AUTOSAR XML (schema 00046)
package /ComponentTypes
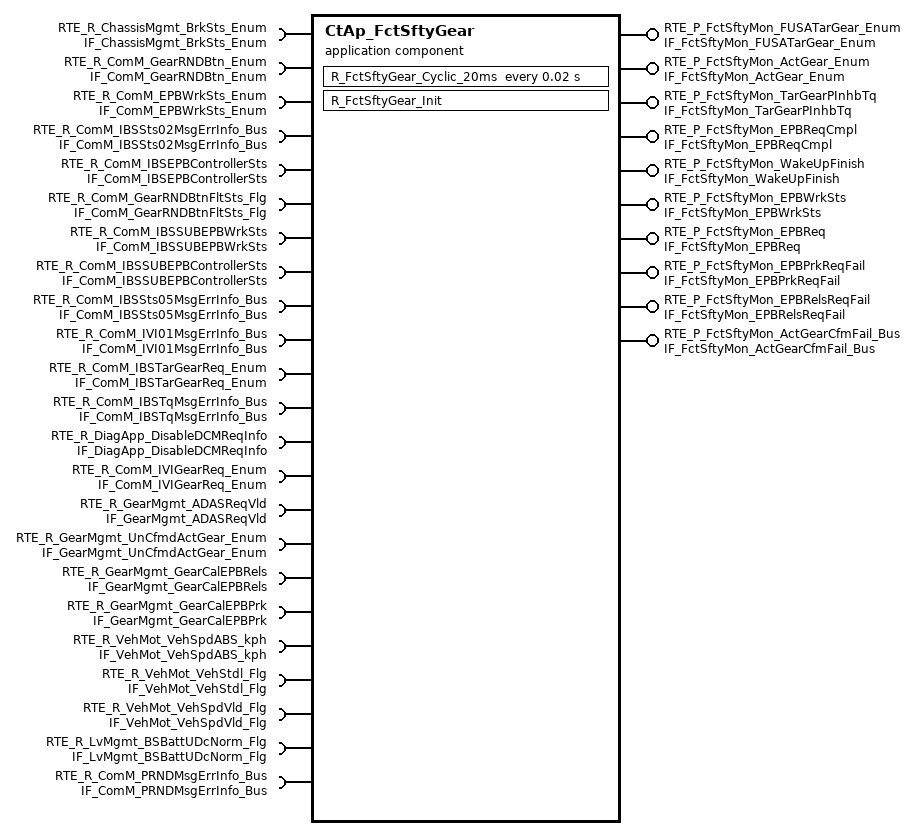
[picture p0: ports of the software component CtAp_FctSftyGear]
  application sw component type CtAp_FctSftyGear
    9 x provide port:
      RTE_P_FctSftyMon_FUSATarGear_Enum: nonqueued-sender-com-spec{data-element=tec_FctSftyMon_FUSATarGear_Enum, init-value=0}, provided-interface=IF_FctSftyMon_FUSATarGear_Enum
      RTE_P_FctSftyMon_ActGear_Enum: nonqueued-sender-com-spec{data-element=tec_FctSftyMon_ActGear_Enum, init-value=0}, provided-interface=IF_FctSftyMon_ActGear_Enum
      RTE_P_FctSftyMon_TarGearPInhbTq: nonqueued-sender-com-spec{data-element=tec_FctSftyMon_TarGearPInhbTq, init-value=0}, provided-interface=IF_FctSftyMon_TarGearPInhbTq
      RTE_P_FctSftyMon_EPBReqCmpl: nonqueued-sender-com-spec{data-element=tec_FctSftyMon_EPBReqCmpl, init-value=0}, provided-interface=IF_FctSftyMon_EPBReqCmpl
      RTE_P_FctSftyMon_WakeUpFinish: nonqueued-sender-com-spec{data-element=tec_FctSftyMon_WakeUpFinish, init-value=0}, provided-interface=IF_FctSftyMon_WakeUpFinish
      RTE_P_FctSftyMon_EPBWrkSts: nonqueued-sender-com-spec{data-element=tec_FctSftyMon_EPBWrkSts, init-value=0}, provided-interface=IF_FctSftyMon_EPBWrkSts
      RTE_P_FctSftyMon_EPBReq: nonqueued-sender-com-spec{data-element=tec_FctSftyMon_EPBReq, init-value=0}, provided-interface=IF_FctSftyMon_EPBReq
      RTE_P_FctSftyMon_EPBPrkReqFail: nonqueued-sender-com-spec{data-element=tec_FctSftyMon_EPBPrkReqFail, init-value=0}, provided-interface=IF_FctSftyMon_EPBPrkReqFail
      RTE_P_FctSftyMon_EPBRelsReqFail: nonqueued-sender-com-spec{data-element=tec_FctSftyMon_EPBRelsReqFail, init-value=0}, provided-interface=IF_FctSftyMon_EPBRelsReqFail
    provide/require port RTE_RP_GearMgmtInfo: nv-provide-com-spec{ram-block-init-value=fields=[GearMgmt_GearMemInfo_Enum:0, GearMgmt_FillAddress:0], rom-block-init-value=fields=[GearMgmt_GearMemInfo_Enum:0, GearMgmt_FillAddress:0], variable=tec_GearMgmtInfo}, nv-require-com-spec{init-value=fields=[GearMgmt_GearMemInfo_Enum:0, GearMgmt_FillAddress:0], variable=tec_GearMgmtInfo}, provided-required-interface=IF_GearMgmtInfo
    14 x require port:
      RTE_R_ChassisMgmt_BrkSts_Enum: nonqueued-receiver-com-spec{data-element=tec_ChassisMgmt_BrkSts_Enum, filter=data-filter-type=ALWAYS, init-value=0}, required-interface=IF_ChassisMgmt_BrkSts_Enum
      RTE_R_ComM_GearRNDBtn_Enum: nonqueued-receiver-com-spec{data-element=tec_ComM_GearRNDBtn_Enum, filter=data-filter-type=ALWAYS, init-value=0}, required-interface=IF_ComM_GearRNDBtn_Enum
      RTE_R_ComM_EPBWrkSts_Enum: nonqueued-receiver-com-spec{data-element=tec_ComM_EPBWrkSts_Enum, filter=data-filter-type=ALWAYS, init-value=0}, required-interface=IF_ComM_EPBWrkSts_Enum
      RTE_R_ComM_IBSSts02MsgErrInfo_Bus: required-interface=IF_ComM_IBSSts02MsgErrInfo_Bus
        required-com-specs:
          data-element=tec_ComM_IBSSts02CRCInfo_Bus, filter=data-filter-type=ALWAYS, init-value=fields=[ComM_MonStatIBSSts02CRCErrorInfo:0, ComM_MonResIBSSts02CRCErrorInfo:0, ComM_ErrStatIBSSts02CRCErrorInfo:0, ComM_ErrResIBSSts02CRCErrorInfo:0]
          data-element=tec_ComM_IBSSts02CRCDTCInfo_Bus, filter=data-filter-type=ALWAYS, init-value=fields=[ComM_MonStatIBSSts02CRCDTCErrorInfo:0, ComM_MonResIBSSts02CRCDTCErrorInfo:0, ComM_ErrStatIBSSts02CRCDTCErrorInfo:0, ComM_ErrResIBSSts02CRCDTCErrorInfo:0]
          data-element=tec_ComM_IBSSts02TimeoutDTCInfo_Bus, filter=data-filter-type=ALWAYS, init-value=fields=[ComM_MonStatIBSSts02TimeoutDTCErrorInfo:0, ComM_MonResIBSSts02TimeoutDTCErrorInfo:0, ComM_ErrStatIBSSts02TimeoutDTCErrorInfo:0, ComM_ErrResIBSSts02TimeoutDTCErrorInfo:0]
          data-element=tec_ComM_IBSSts02E2ETimeoutInfo_Bus, filter=data-filter-type=ALWAYS, init-value=fields=[ComM_MonStatIBSSts02E2ETimeoutInfo:0, ComM_MonResIBSSts02E2ETimeoutInfo:0, ComM_ErrStatIBSSts02E2ETimeoutInfo:0, ComM_ErrResIBSSts02E2ETimeoutInfo:0]
      RTE_R_ComM_IBSEPBControllerSts: nonqueued-receiver-com-spec{data-element=tec_ComM_IBSEPBControllerSts, filter=data-filter-type=ALWAYS, init-value=0}, required-interface=IF_ComM_IBSEPBControllerSts
      RTE_R_ComM_GearRNDBtnFltSts_Flg: nonqueued-receiver-com-spec{data-element=tec_ComM_GearRNDBtnFltSts_Flg, filter=data-filter-type=ALWAYS, init-value=0}, required-interface=IF_ComM_GearRNDBtnFltSts_Flg
      RTE_R_ComM_IBSSUBEPBWrkSts: nonqueued-receiver-com-spec{data-element=tec_ComM_IBSSUBEPBWrkSts, filter=data-filter-type=ALWAYS, init-value=0}, required-interface=IF_ComM_IBSSUBEPBWrkSts
      RTE_R_ComM_IBSSUBEPBControllerSts: nonqueued-receiver-com-spec{data-element=tec_ComM_IBSSUBEPBControllerSts, filter=data-filter-type=ALWAYS, init-value=0}, required-interface=IF_ComM_IBSSUBEPBControllerSts
      RTE_R_ComM_IBSSts05MsgErrInfo_Bus: required-interface=IF_ComM_IBSSts05MsgErrInfo_Bus
        required-com-specs:
          data-element=tec_ComM_IBSSts05CRCDTCInfo_Bus, filter=data-filter-type=ALWAYS, init-value=fields=[ComM_MonStatIBSSts05CRCDTCErrorInfo:0, ComM_MonResIBSSts05CRCDTCErrorInfo:0, ComM_ErrStatIBSSts05CRCDTCErrorInfo:0, ComM_ErrResIBSSts05CRCDTCErrorInfo:0]
          data-element=tec_ComM_IBSSts05TimeoutDTCInfo_Bus, filter=data-filter-type=ALWAYS, init-value=fields=[ComM_MonStatIBSSts05TimeoutDTCErrorInfo:0, ComM_MonResIBSSts05TimeoutDTCErrorInfo:0, ComM_ErrStatIBSSts05TimeoutDTCErrorInfo:0, ComM_ErrResIBSSts05TimeoutDTCErrorInfo:0]
          data-element=tec_ComM_IBSSts05TimeoutInfo_Bus, filter=data-filter-type=ALWAYS, init-value=fields=[ComM_MonStatIBSSts05TimeoutInfo:0, ComM_MonResIBSSts05TimeoutInfo:0, ComM_ErrStatIBSSts05TimeoutInfo:0, ComM_ErrResIBSSts05TimeoutInfo:0]
          data-element=tec_ComM_IBSSts05CRCInfo_Bus, filter=data-filter-type=ALWAYS, init-value=fields=[ComM_MonStatIBSSts05CRCErrorInfo:0, ComM_MonResIBSSts05CRCErrorInfo:0, ComM_ErrStatIBSSts05CRCErrorInfo:0, ComM_ErrResIBSSts05CRCErrorInfo:0]
          data-element=tec_ComM_IBSSts05E2ETimeoutInfo_Bus, filter=data-filter-type=ALWAYS, init-value=fields=[ComM_MonStatIBSSts05E2ETimeoutInfo:0, ComM_MonResIBSSts05E2ETimeoutInfo:0, ComM_ErrStatIBSSts05E2ETimeoutInfo:0, ComM_ErrResIBSSts05E2ETimeoutInfo:0]
      RTE_R_ComM_IVI01MsgErrInfo_Bus: required-interface=IF_ComM_IVI01MsgErrInfo_Bus
        required-com-specs:
          data-element=tec_ComM_IVI01CRCInfo_Bus, filter=data-filter-type=ALWAYS, init-value=fields=[ComM_MonStatIVI01CRCErrorInfo:0, ComM_MonResIVI01CRCErrorInfo:0, ComM_ErrStatIVI01CRCErrorInfo:0, ComM_ErrResIVI01CRCErrorInfo:0]
          data-element=tec_ComM_IVI01E2ETimeoutInfo_Bus, filter=data-filter-type=ALWAYS, init-value=fields=[ComM_MonStatIVI01E2ETimeoutInfo:0, ComM_MonResIVI01E2ETimeoutInfo:0, ComM_ErrStatIVI01E2ETimeoutInfo:0, ComM_ErrResIVI01E2ETimeoutInfo:0]
      RTE_R_ComM_IBSTarGearReq_Enum: nonqueued-receiver-com-spec{data-element=tec_ComM_IBSTarGearReq_Enum, filter=data-filter-type=ALWAYS, init-value=0}, required-interface=IF_ComM_IBSTarGearReq_Enum
      RTE_R_ComM_IBSTqMsgErrInfo_Bus: required-interface=IF_ComM_IBSTqMsgErrInfo_Bus
        required-com-specs:
          data-element=tec_ComM_IBSTqCRCDTCInfo_Bus, filter=data-filter-type=ALWAYS, init-value=fields=[ComM_MonStatIBSTqCRCDTCErrorInfo:0, ComM_MonResIBSTqCRCDTCErrorInfo:0, ComM_ErrStatIBSTqCRCDTCErrorInfo:0, ComM_ErrResIBSTqCRCDTCErrorInfo:0]
          data-element=tec_ComM_IBSTqTimeoutDTCInfo_Bus, filter=data-filter-type=ALWAYS, init-value=fields=[ComM_MonStatIBSTqTimeoutDTCErrorInfo:0, ComM_MonResIBSTqTimeoutDTCErrorInfo:0, ComM_ErrStatIBSTqTimeoutDTCErrorInfo:0, ComM_ErrResIBSTqTimeoutDTCErrorInfo:0]
          data-element=tec_ComM_IBSTqCRCInfo_Bus, filter=data-filter-type=ALWAYS, init-value=fields=[ComM_MonStatIBSTqCRCErrorInfo:0, ComM_MonResIBSTqCRCErrorInfo:0, ComM_ErrStatIBSTqCRCErrorInfo:0, ComM_ErrResIBSTqCRCErrorInfo:0]
          data-element=tec_ComM_IBSTqE2ETimeoutInfo_Bus, filter=data-filter-type=ALWAYS, init-value=fields=[ComM_MonStatIBSTqE2ETimeoutInfo:0, ComM_MonResIBSTqE2ETimeoutInfo:0, ComM_ErrStatIBSTqE2ETimeoutInfo:0, ComM_ErrResIBSTqE2ETimeoutInfo:0]
      RTE_R_DiagApp_DisableDCMReqInfo: nonqueued-receiver-com-spec{data-element=tec_DiagApp_DisableDCMReqInfo, filter=data-filter-type=ALWAYS, init-value=0}, required-interface=IF_DiagApp_DisableDCMReqInfo
      RTE_R_ComM_IVIGearReq_Enum: nonqueued-receiver-com-spec{data-element=tec_ComM_IVIGearReq_Enum, filter=data-filter-type=ALWAYS, init-value=0}, required-interface=IF_ComM_IVIGearReq_Enum
    provide port RTE_P_FctSftyMon_ActGearCfmFail_Bus: nonqueued-sender-com-spec{data-element=tec_FctSftyMon_ActGearCfmFail_Bus, init-value=fields=[FctSftyMon_MonStatActGearCfmFail:0, FctSftyMon_MonResActGearCfmFail:0, FctSftyMon_ErrStatActGearCfmFail:0, FctSftyMon_ErrResActGearCfmFail:0]}, provided-interface=IF_FctSftyMon_ActGearCfmFail_Bus
    9 x require port:
      RTE_R_GearMgmt_ADASReqVld: nonqueued-receiver-com-spec{data-element=tec_GearMgmt_ADASReqVld, filter=data-filter-type=ALWAYS, init-value=0}, required-interface=IF_GearMgmt_ADASReqVld
      RTE_R_GearMgmt_UnCfmdActGear_Enum: nonqueued-receiver-com-spec{data-element=tec_GearMgmt_UnCfmdActGear_Enum, filter=data-filter-type=ALWAYS, init-value=0}, required-interface=IF_GearMgmt_UnCfmdActGear_Enum
      RTE_R_GearMgmt_GearCalEPBRels: nonqueued-receiver-com-spec{data-element=tec_GearMgmt_GearCalEPBRels, filter=data-filter-type=ALWAYS, init-value=0}, required-interface=IF_GearMgmt_GearCalEPBRels
      RTE_R_GearMgmt_GearCalEPBPrk: nonqueued-receiver-com-spec{data-element=tec_GearMgmt_GearCalEPBPrk, filter=data-filter-type=ALWAYS, init-value=0}, required-interface=IF_GearMgmt_GearCalEPBPrk
      RTE_R_VehMot_VehSpdABS_kph: nonqueued-receiver-com-spec{data-element=tec_VehMot_VehSpdABS_kph, filter=data-filter-type=ALWAYS, init-value=0}, required-interface=IF_VehMot_VehSpdABS_kph
      RTE_R_VehMot_VehStdl_Flg: nonqueued-receiver-com-spec{data-element=tec_VehMot_VehStdl_Flg, filter=data-filter-type=ALWAYS, init-value=0}, required-interface=IF_VehMot_VehStdl_Flg
      RTE_R_VehMot_VehSpdVld_Flg: nonqueued-receiver-com-spec{data-element=tec_VehMot_VehSpdVld_Flg, filter=data-filter-type=ALWAYS, init-value=0}, required-interface=IF_VehMot_VehSpdVld_Flg
      RTE_R_LvMgmt_BSBattUDcNorm_Flg: nonqueued-receiver-com-spec{data-element=tec_LvMgmt_BSBattUDcNorm_Flg, filter=data-filter-type=ALWAYS, init-value=0}, required-interface=IF_LvMgmt_BSBattUDcNorm_Flg
      RTE_R_ComM_PRNDMsgErrInfo_Bus: required-interface=IF_ComM_PRNDMsgErrInfo_Bus
        required-com-specs:
          data-element=tec_ComM_PRNDTimeoutInfo_Bus, filter=data-filter-type=ALWAYS, init-value=fields=[ComM_MonStatPRNDTimeoutInfo:0, ComM_MonResPRNDTimeoutInfo:0, ComM_ErrStatPRNDTimeoutInfo:0, ComM_ErrResPRNDTimeoutInfo:0]
          data-element=tec_ComM_PRNDCRCDTCInfo_Bus, filter=data-filter-type=ALWAYS, init-value=fields=[ComM_MonStatPRNDCRCDTCErrorInfo:0, ComM_MonResPRNDCRCDTCErrorInfo:0, ComM_ErrStatPRNDCRCDTCErrorInfo:0, ComM_ErrResPRNDCRCDTCErrorInfo:0]
          data-element=tec_ComM_PRNDCRCInfo_Bus, filter=data-filter-type=ALWAYS, init-value=fields=[ComM_MonStatPRNDCRCErrorInfo:0, ComM_MonResPRNDCRCErrorInfo:0, ComM_ErrStatPRNDCRCErrorInfo:0, ComM_ErrResPRNDCRCErrorInfo:0]
          data-element=tec_ComM_PRNDTimeoutDTCInfo_Bus, filter=data-filter-type=ALWAYS, init-value=fields=[ComM_MonStatPRNDTimeoutDTCErrorInfo:0, ComM_MonResPRNDTimeoutDTCErrorInfo:0, ComM_ErrStatPRNDTimeoutDTCErrorInfo:0, ComM_ErrResPRNDTimeoutDTCErrorInfo:0]
          data-element=tec_ComM_PRNDE2ETimeoutInfo_Bus, filter=data-filter-type=ALWAYS, init-value=fields=[ComM_MonStatPRNDE2ETimeoutInfo:0, ComM_MonResPRNDE2ETimeoutInfo:0, ComM_ErrStatPRNDE2ETimeoutInfo:0, ComM_ErrResPRNDE2ETimeoutInfo:0]
    behavior CtAp_FctSftyGear_InternalBehavior
      timing event TMT_R_FctSftyGear_Cyclic_20ms: start-on-event=R_FctSftyGear_Cyclic_20ms, period=0.02
      init event CtAp_FctSftyGear_InitEvent: start-on-event=R_FctSftyGear_Init
      runnable R_FctSftyGear_Cyclic_20ms
        data-receive-point-by-arguments:
          29 x access:
            REC_RTE_RP_GearMgmtInfo_tec_GearMgmtInfo: accessed-variable=RTE_RP_GearMgmtInfo.tec_GearMgmtInfo
            REC_RTE_R_ChassisMgmt_BrkSts_Enum_tec_ChassisMgmt_BrkSts_Enum: accessed-variable=RTE_R_ChassisMgmt_BrkSts_Enum.tec_ChassisMgmt_BrkSts_Enum
            REC_RTE_R_ComM_EPBWrkSts_Enum_tec_ComM_EPBWrkSts_Enum: accessed-variable=RTE_R_ComM_EPBWrkSts_Enum.tec_ComM_EPBWrkSts_Enum
            REC_RTE_R_ComM_GearRNDBtnFltSts_Flg_tec_ComM_GearRNDBtnFltSts_Flg: accessed-variable=RTE_R_ComM_GearRNDBtnFltSts_Flg.tec_ComM_GearRNDBtnFltSts_Flg
            REC_RTE_R_ComM_GearRNDBtn_Enum_tec_ComM_GearRNDBtn_Enum: accessed-variable=RTE_R_ComM_GearRNDBtn_Enum.tec_ComM_GearRNDBtn_Enum
            REC_RTE_R_ComM_IBSEPBControllerSts_tec_ComM_IBSEPBControllerSts: accessed-variable=RTE_R_ComM_IBSEPBControllerSts.tec_ComM_IBSEPBControllerSts
            REC_RTE_R_ComM_IBSSUBEPBControllerSts_tec_ComM_IBSSUBEPBControllerSts: accessed-variable=RTE_R_ComM_IBSSUBEPBControllerSts.tec_ComM_IBSSUBEPBControllerSts
            REC_RTE_R_ComM_IBSSUBEPBWrkSts_tec_ComM_IBSSUBEPBWrkSts: accessed-variable=RTE_R_ComM_IBSSUBEPBWrkSts.tec_ComM_IBSSUBEPBWrkSts
            REC_RTE_R_ComM_IVIGearReq_Enum_tec_ComM_IVIGearReq_Enum: accessed-variable=RTE_R_ComM_IVIGearReq_Enum.tec_ComM_IVIGearReq_Enum
            REC_RTE_R_DiagApp_DisableDCMReqInfo_tec_DiagApp_DisableDCMReqInfo: accessed-variable=RTE_R_DiagApp_DisableDCMReqInfo.tec_DiagApp_DisableDCMReqInfo
            REC_RTE_R_GearMgmt_ADASReqVld_tec_GearMgmt_ADASReqVld: accessed-variable=RTE_R_GearMgmt_ADASReqVld.tec_GearMgmt_ADASReqVld
            REC_RTE_R_GearMgmt_GearCalEPBPrk_tec_GearMgmt_GearCalEPBPrk: accessed-variable=RTE_R_GearMgmt_GearCalEPBPrk.tec_GearMgmt_GearCalEPBPrk
            REC_RTE_R_GearMgmt_GearCalEPBRels_tec_GearMgmt_GearCalEPBRels: accessed-variable=RTE_R_GearMgmt_GearCalEPBRels.tec_GearMgmt_GearCalEPBRels
            REC_RTE_R_GearMgmt_UnCfmdActGear_Enum_tec_GearMgmt_UnCfmdActGear_Enum: accessed-variable=RTE_R_GearMgmt_UnCfmdActGear_Enum.tec_GearMgmt_UnCfmdActGear_Enum
            REC_RTE_R_LvMgmt_BSBattUDcNorm_Flg_tec_LvMgmt_BSBattUDcNorm_Flg: accessed-variable=RTE_R_LvMgmt_BSBattUDcNorm_Flg.tec_LvMgmt_BSBattUDcNorm_Flg
            REC_RTE_R_VehMot_VehSpdABS_kph_tec_VehMot_VehSpdABS_kph: accessed-variable=RTE_R_VehMot_VehSpdABS_kph.tec_VehMot_VehSpdABS_kph
            REC_RTE_R_VehMot_VehSpdVld_Flg_tec_VehMot_VehSpdVld_Flg: accessed-variable=RTE_R_VehMot_VehSpdVld_Flg.tec_VehMot_VehSpdVld_Flg
            REC_RTE_R_VehMot_VehStdl_Flg_tec_VehMot_VehStdl_Flg: accessed-variable=RTE_R_VehMot_VehStdl_Flg.tec_VehMot_VehStdl_Flg
            REC_RTE_R_ComM_IBSSts02MsgErrInfo_Bus_tec_ComM_IBSSts02CRCInfo_Bus: accessed-variable=RTE_R_ComM_IBSSts02MsgErrInfo_Bus.tec_ComM_IBSSts02CRCInfo_Bus
            REC_RTE_R_ComM_IBSSts02MsgErrInfo_Bus_tec_ComM_IBSSts02E2ETimeoutInfo_Bus: accessed-variable=RTE_R_ComM_IBSSts02MsgErrInfo_Bus.tec_ComM_IBSSts02E2ETimeoutInfo_Bus
            REC_RTE_R_ComM_IBSSts05MsgErrInfo_Bus_tec_ComM_IBSSts05CRCInfo_Bus: accessed-variable=RTE_R_ComM_IBSSts05MsgErrInfo_Bus.tec_ComM_IBSSts05CRCInfo_Bus
            REC_RTE_R_ComM_IBSSts05MsgErrInfo_Bus_tec_ComM_IBSSts05E2ETimeoutInfo_Bus: accessed-variable=RTE_R_ComM_IBSSts05MsgErrInfo_Bus.tec_ComM_IBSSts05E2ETimeoutInfo_Bus
            REC_RTE_R_ComM_IBSTqMsgErrInfo_Bus_tec_ComM_IBSTqCRCInfo_Bus: accessed-variable=RTE_R_ComM_IBSTqMsgErrInfo_Bus.tec_ComM_IBSTqCRCInfo_Bus
            REC_RTE_R_ComM_IBSTqMsgErrInfo_Bus_tec_ComM_IBSTqE2ETimeoutInfo_Bus: accessed-variable=RTE_R_ComM_IBSTqMsgErrInfo_Bus.tec_ComM_IBSTqE2ETimeoutInfo_Bus
            REC_RTE_R_ComM_IVI01MsgErrInfo_Bus_tec_ComM_IVI01CRCInfo_Bus: accessed-variable=RTE_R_ComM_IVI01MsgErrInfo_Bus.tec_ComM_IVI01CRCInfo_Bus
            REC_RTE_R_ComM_IVI01MsgErrInfo_Bus_tec_ComM_IVI01E2ETimeoutInfo_Bus: accessed-variable=RTE_R_ComM_IVI01MsgErrInfo_Bus.tec_ComM_IVI01E2ETimeoutInfo_Bus
            REC_RTE_R_ComM_PRNDMsgErrInfo_Bus_tec_ComM_PRNDCRCInfo_Bus: accessed-variable=RTE_R_ComM_PRNDMsgErrInfo_Bus.tec_ComM_PRNDCRCInfo_Bus
            REC_RTE_R_ComM_PRNDMsgErrInfo_Bus_tec_ComM_PRNDE2ETimeoutInfo_Bus: accessed-variable=RTE_R_ComM_PRNDMsgErrInfo_Bus.tec_ComM_PRNDE2ETimeoutInfo_Bus
            REC_RTE_R_ComM_IBSTarGearReq_Enum_tec_ComM_IBSTarGearReq_Enum: accessed-variable=RTE_R_ComM_IBSTarGearReq_Enum.tec_ComM_IBSTarGearReq_Enum
        data-send-points:
          11 x access:
            SEND_RTE_P_FctSftyMon_ActGearCfmFail_Bus_tec_FctSftyMon_ActGearCfmFail_Bus: accessed-variable=RTE_P_FctSftyMon_ActGearCfmFail_Bus.tec_FctSftyMon_ActGearCfmFail_Bus
            SEND_RTE_P_FctSftyMon_ActGear_Enum_tec_FctSftyMon_ActGear_Enum: accessed-variable=RTE_P_FctSftyMon_ActGear_Enum.tec_FctSftyMon_ActGear_Enum
            SEND_RTE_P_FctSftyMon_EPBPrkReqFail_tec_FctSftyMon_EPBPrkReqFail: accessed-variable=RTE_P_FctSftyMon_EPBPrkReqFail.tec_FctSftyMon_EPBPrkReqFail
            SEND_RTE_P_FctSftyMon_EPBRelsReqFail_tec_FctSftyMon_EPBRelsReqFail: accessed-variable=RTE_P_FctSftyMon_EPBRelsReqFail.tec_FctSftyMon_EPBRelsReqFail
            SEND_RTE_P_FctSftyMon_EPBReq_tec_FctSftyMon_EPBReq: accessed-variable=RTE_P_FctSftyMon_EPBReq.tec_FctSftyMon_EPBReq
            SEND_RTE_P_FctSftyMon_EPBReqCmpl_tec_FctSftyMon_EPBReqCmpl: accessed-variable=RTE_P_FctSftyMon_EPBReqCmpl.tec_FctSftyMon_EPBReqCmpl
            SEND_RTE_P_FctSftyMon_EPBWrkSts_tec_FctSftyMon_EPBWrkSts: accessed-variable=RTE_P_FctSftyMon_EPBWrkSts.tec_FctSftyMon_EPBWrkSts
            SEND_RTE_P_FctSftyMon_FUSATarGear_Enum_tec_FctSftyMon_FUSATarGear_Enum: accessed-variable=RTE_P_FctSftyMon_FUSATarGear_Enum.tec_FctSftyMon_FUSATarGear_Enum
            SEND_RTE_P_FctSftyMon_TarGearPInhbTq_tec_FctSftyMon_TarGearPInhbTq: accessed-variable=RTE_P_FctSftyMon_TarGearPInhbTq.tec_FctSftyMon_TarGearPInhbTq
            SEND_RTE_P_FctSftyMon_WakeUpFinish_tec_FctSftyMon_WakeUpFinish: accessed-variable=RTE_P_FctSftyMon_WakeUpFinish.tec_FctSftyMon_WakeUpFinish
            SEND_RTE_RP_GearMgmtInfo_tec_GearMgmtInfo: accessed-variable=RTE_RP_GearMgmtInfo.tec_GearMgmtInfo
      runnable R_FctSftyGear_Init
  swc implementation CtAp_FctSftyGear_Implementation: behavior=CtAp_FctSftyGear_InternalBehavior
